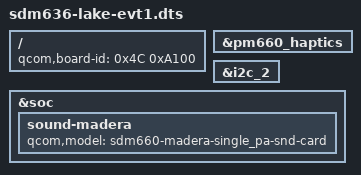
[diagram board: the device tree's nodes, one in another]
/* Copyright (c) 2018, Motorola Mobility Inc. All rights reserved.
 *
 * This program is free software; you can redistribute it and/or modify
 * it under the terms of the GNU General Public License version 2 and
 * only version 2 as published by the Free Software Foundation.
 *
 * This program is distributed in the hope that it will be useful,
 * but WITHOUT ANY WARRANTY; without even the implied warranty of
 * MERCHANTABILITY or FITNESS FOR A PARTICULAR PURPOSE.  See the
 * GNU General Public License for more details.
 */


/dts-v1/;

#include "sdm636.dtsi"
#include "sdm636-lake.dtsi"

/ {
	qcom,board-id = <0x4C 0xA100>;
};

&pm660_haptics {
	status = "okay";
};

&i2c_2 {
	/delete-node/ aw869x_haptic@5B;
};

&soc {
	sound-madera {
		qcom,model = "sdm660-madera-single_pa-snd-card";
	};
};
